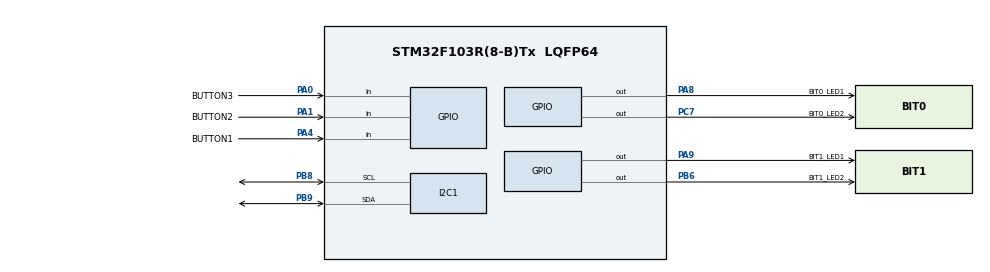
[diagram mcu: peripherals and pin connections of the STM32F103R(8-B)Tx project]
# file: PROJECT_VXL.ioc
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Mcu.Family=STM32F1
Mcu.Name=STM32F103R(8-B)Tx
Mcu.Package=LQFP64
NVIC.PriorityGroup=NVIC_PRIORITYGROUP_4
NVIC.TIM2_IRQn=true\:0\:0\:false\:false\:true\:true\:true\:true
PA0-WKUP.GPIO_Label=BUTTON3
PA0-WKUP.Signal=GPIO_Input
PA1.GPIO_Label=BUTTON2
PA1.Signal=GPIO_Input
PA4.GPIO_Label=BUTTON1
PA4.Signal=GPIO_Input
PA8.GPIO_Label=BIT0_LED1
PA8.Signal=GPIO_Output
PA9.GPIO_Label=BIT1_LED1
PA9.Signal=GPIO_Output
PB6.GPIO_Label=BIT1_LED2
PB6.Signal=GPIO_Output
PB8.Mode=I2C
PB8.Signal=I2C1_SCL
PB9.Mode=I2C
PB9.Signal=I2C1_SDA
PC7.GPIO_Label=BIT0_LED2
PC7.Signal=GPIO_Output
ProjectManager.HeapSize=0x200
ProjectManager.StackSize=0x400
ProjectManager.TargetToolchain=STM32CubeIDE
RCC.APB1Freq_Value=8000000
RCC.APB2Freq_Value=8000000
TIM2.Period=9
TIM2.Prescaler=7999
VP_SYS_VS_ND.Mode=No_Debug
VP_TIM2_VS_ClockSourceINT.Mode=Internal
board=custom

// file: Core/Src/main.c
/* USER CODE BEGIN Header */
/**
  ******************************************************************************
  * @file           : main.c
  * @brief          : Main program body
  ******************************************************************************
  * @attention
  *
  * Copyright (c) 2024 STMicroelectronics.
  * All rights reserved.
  *
  * This software is licensed under terms that can be found in the LICENSE file
  * in the root directory of this software component.
  * If no LICENSE file comes with this software, it is provided AS-IS.
  *
  ******************************************************************************
  */
/* USER CODE END Header */
#include "main.h"

/* USER CODE BEGIN Includes */
#include "global.h"
/* USER CODE END Includes */

I2C_HandleTypeDef hi2c1;

TIM_HandleTypeDef htim2;

void SystemClock_Config(void);
static void MX_GPIO_Init(void);
static void MX_I2C1_Init(void);
static void MX_TIM2_Init(void);

int main(void)
{

  /* MCU Configuration--------------------------------------------------------*/

  /* Reset of all peripherals, Initializes the Flash interface and the Systick. */
  HAL_Init();

  /* Configure the system clock */
  SystemClock_Config();

  /* Initialize all configured peripherals */
  MX_GPIO_Init();
  MX_I2C1_Init();
  MX_TIM2_Init();
  /* USER CODE BEGIN 2 */
  HAL_TIM_Base_Start_IT(&htim2) ;
  /* USER CODE END 2 */

  /* Infinite loop */
  /* USER CODE BEGIN WHILE */
  lcd_init();
  SCH_Init();
  SCH_Add_Task(fsm_automatic,0,10);
  SCH_Add_Task(fsm_setting,0,10);
  SCH_Add_Task(fsm_manual,0,10);
  SCH_Add_Task(setuptrangthai,0,10);
  while (1)
  {
    /* USER CODE END WHILE */

    /* USER CODE BEGIN 3 */
      SCH_Dispatch_Tasks();
      __WFI();  // Ch�? đến khi có ngắt
  }
  /* USER CODE END 3 */
}

void SystemClock_Config(void)
{
  RCC_OscInitTypeDef RCC_OscInitStruct = {0};
  RCC_ClkInitTypeDef RCC_ClkInitStruct = {0};

  /** Initializes the RCC Oscillators according to the specified parameters
  * in the RCC_OscInitTypeDef structure.
  */
  RCC_OscInitStruct.OscillatorType = RCC_OSCILLATORTYPE_HSI;
  RCC_OscInitStruct.HSIState = RCC_HSI_ON;
  RCC_OscInitStruct.HSICalibrationValue = RCC_HSICALIBRATION_DEFAULT;
  RCC_OscInitStruct.PLL.PLLState = RCC_PLL_NONE;
  if (HAL_RCC_OscConfig(&RCC_OscInitStruct) != HAL_OK)
  {
    Error_Handler();
  }

  /** Initializes the CPU, AHB and APB buses clocks
  */
  RCC_ClkInitStruct.ClockType = RCC_CLOCKTYPE_HCLK|RCC_CLOCKTYPE_SYSCLK
                              |RCC_CLOCKTYPE_PCLK1|RCC_CLOCKTYPE_PCLK2;
  RCC_ClkInitStruct.SYSCLKSource = RCC_SYSCLKSOURCE_HSI;
  RCC_ClkInitStruct.AHBCLKDivider = RCC_SYSCLK_DIV1;
  RCC_ClkInitStruct.APB1CLKDivider = RCC_HCLK_DIV1;
  RCC_ClkInitStruct.APB2CLKDivider = RCC_HCLK_DIV1;

  if (HAL_RCC_ClockConfig(&RCC_ClkInitStruct, FLASH_LATENCY_0) != HAL_OK)
  {
    Error_Handler();
  }
}

static void MX_I2C1_Init(void)
{

  hi2c1.Instance = I2C1;
  hi2c1.Init.ClockSpeed = 100000;
  hi2c1.Init.DutyCycle = I2C_DUTYCYCLE_2;
  hi2c1.Init.OwnAddress1 = 0;
  hi2c1.Init.AddressingMode = I2C_ADDRESSINGMODE_7BIT;
  hi2c1.Init.DualAddressMode = I2C_DUALADDRESS_DISABLE;
  hi2c1.Init.OwnAddress2 = 0;
  hi2c1.Init.GeneralCallMode = I2C_GENERALCALL_DISABLE;
  hi2c1.Init.NoStretchMode = I2C_NOSTRETCH_DISABLE;
  if (HAL_I2C_Init(&hi2c1) != HAL_OK)
  {
    Error_Handler();
  }

}

static void MX_TIM2_Init(void)
{

  TIM_ClockConfigTypeDef sClockSourceConfig = {0};
  TIM_MasterConfigTypeDef sMasterConfig = {0};

  htim2.Instance = TIM2;
  htim2.Init.Prescaler = 7999;
  htim2.Init.CounterMode = TIM_COUNTERMODE_UP;
  htim2.Init.Period = 9;
  htim2.Init.ClockDivision = TIM_CLOCKDIVISION_DIV1;
  htim2.Init.AutoReloadPreload = TIM_AUTORELOAD_PRELOAD_DISABLE;
  if (HAL_TIM_Base_Init(&htim2) != HAL_OK)
  {
    Error_Handler();
  }
  sClockSourceConfig.ClockSource = TIM_CLOCKSOURCE_INTERNAL;
  if (HAL_TIM_ConfigClockSource(&htim2, &sClockSourceConfig) != HAL_OK)
  {
    Error_Handler();
  }
  sMasterConfig.MasterOutputTrigger = TIM_TRGO_RESET;
  sMasterConfig.MasterSlaveMode = TIM_MASTERSLAVEMODE_DISABLE;
  if (HAL_TIMEx_MasterConfigSynchronization(&htim2, &sMasterConfig) != HAL_OK)
  {
    Error_Handler();
  }

}

static void MX_GPIO_Init(void)
{
  GPIO_InitTypeDef GPIO_InitStruct = {0};

  /* GPIO Ports Clock Enable */
  __HAL_RCC_GPIOA_CLK_ENABLE();
  __HAL_RCC_GPIOC_CLK_ENABLE();
  __HAL_RCC_GPIOB_CLK_ENABLE();

  /*Configure GPIO pin Output Level */
  HAL_GPIO_WritePin(BIT0_LED2_GPIO_Port, BIT0_LED2_Pin, GPIO_PIN_RESET);

  /*Configure GPIO pin Output Level */
  HAL_GPIO_WritePin(GPIOA, BIT0_LED1_Pin|BIT1_LED1_Pin, GPIO_PIN_RESET);

  /*Configure GPIO pin Output Level */
  HAL_GPIO_WritePin(BIT1_LED2_GPIO_Port, BIT1_LED2_Pin, GPIO_PIN_RESET);

  /*Configure GPIO pins : BUTTON3_Pin BUTTON2_Pin BUTTON1_Pin */
  GPIO_InitStruct.Pin = BUTTON3_Pin|BUTTON2_Pin|BUTTON1_Pin;
  GPIO_InitStruct.Mode = GPIO_MODE_INPUT;
  GPIO_InitStruct.Pull = GPIO_NOPULL;
  HAL_GPIO_Init(GPIOA, &GPIO_InitStruct);

  /*Configure GPIO pin : BIT0_LED2_Pin */
  GPIO_InitStruct.Pin = BIT0_LED2_Pin;
  GPIO_InitStruct.Mode = GPIO_MODE_OUTPUT_PP;
  GPIO_InitStruct.Pull = GPIO_NOPULL;
  GPIO_InitStruct.Speed = GPIO_SPEED_FREQ_LOW;
  HAL_GPIO_Init(BIT0_LED2_GPIO_Port, &GPIO_InitStruct);

  /*Configure GPIO pins : BIT0_LED1_Pin BIT1_LED1_Pin */
  GPIO_InitStruct.Pin = BIT0_LED1_Pin|BIT1_LED1_Pin;
  GPIO_InitStruct.Mode = GPIO_MODE_OUTPUT_PP;
  GPIO_InitStruct.Pull = GPIO_NOPULL;
  GPIO_InitStruct.Speed = GPIO_SPEED_FREQ_LOW;
  HAL_GPIO_Init(GPIOA, &GPIO_InitStruct);

  /*Configure GPIO pin : BIT1_LED2_Pin */
  GPIO_InitStruct.Pin = BIT1_LED2_Pin;
  GPIO_InitStruct.Mode = GPIO_MODE_OUTPUT_PP;
  GPIO_InitStruct.Pull = GPIO_NOPULL;
  GPIO_InitStruct.Speed = GPIO_SPEED_FREQ_LOW;
  HAL_GPIO_Init(BIT1_LED2_GPIO_Port, &GPIO_InitStruct);

}

/* USER CODE BEGIN 4 */
void HAL_TIM_PeriodElapsedCallback ( TIM_HandleTypeDef * htim )
{
	        // Xử lý khi Timer2 hết hạn
	        timer_run();
	        SCH_Update();
	        getKeyInput();
	        // Check button input with debounces
}
/* USER CODE END 4 */

void Error_Handler(void)
{
  __disable_irq();
  while (1)
  {
  }
}
